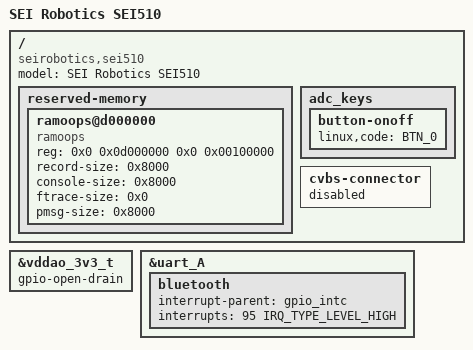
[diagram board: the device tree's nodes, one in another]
// SPDX-License-Identifier: (GPL-2.0+ OR MIT)
/*
 * Copyright (c) 2020 BayLibre SAS. All rights reserved.
 */

/dts-v1/;
/plugin/;

#include <dt-bindings/gpio/gpio.h>
#include <dt-bindings/gpio/meson-g12a-gpio.h>
#include <dt-bindings/input/input.h>
#include <dt-bindings/interrupt-controller/irq.h>
#include <dt-bindings/interrupt-controller/arm-gic.h>

/ {
  compatible = "seirobotics,sei510", "amlogic,g12a";
  model = "SEI Robotics SEI510";
  fragment@101 {
        target-path = "/";

        __overlay__ {
                reserved-memory {
                        #address-cells = <2>;
                        #size-cells = <2>;
                        ramoops@d000000 {
                                compatible = "ramoops";
                                reg = <0x0 0x0d000000 0x0 0x00100000>;
                                record-size = <0x8000>;
                                console-size = <0x8000>;
                                ftrace-size = <0x0>;
                                pmsg-size = <0x8000>;
                        };
                };

                adc_keys {
                        button-onoff {
                                linux,code = <BTN_0>;
                        };
                };

                cvbs-connector {
                        status = "disabled";
                };
        };
  };
};

&vddao_3v3_t {
	gpio-open-drain;
};

&uart_A {
	bluetooth {
        interrupt-parent = <&gpio_intc>;
        interrupts = <95 IRQ_TYPE_LEVEL_HIGH>;
		interrupt-names = "host-wakeup";
    };
};
